# CH585SFR register map
Vendor: WCH Ltd.; Series: CH58x; File version: 1.0
WCH wireless MCU CH58x Family Support, Drivers
CPU: RISC-V r0p0, little endian, no MPU, no FPU, 2 interrupt priority bits
Registers are 8-bit, Read or Write, reset 0x0 unless marked. A register's access mark holds for its fields unless they carry their own. Offsets are from the block's base; lines under a group give offsets from that group; [hi:lo] are bit positions; {n}, {i} and the like mark numbered series; 'fields as' and 'values as' point back to an identical list; <NAME> marks a mode.

## Memory map
0x40001000 SYS size 0x400 — System Control Register
0x40001000 RTC blocks up to offset 0x3F — Real time clock
0x40001000 System_control blocks up to offset 0x54 — System control related registers
0x40001000 TouchKey blocks up to offset 0x58 — Touch buttons
0x40001000 ADC blocks up to offset 0x8E — Analog to Digital Converter
0x40001000 GPIO blocks up to offset 0xDC — General porpose intput output
0x40002000 TMR0 size 0x400 — Timer0 register
0x40002400 TMR1 size 0x400 — Timer1 register
0x40002800 TMR2 size 0x400 — Timer2 register
0x40002C00 TMR3 size 0x400 — Timer3 register
0x40003000 UART0 size 0x400
0x40003400 UART1 size 0x400
0x40003800 UART2 size 0x400
0x40003C00 UART3 size 0x400
0x40004000 SPI0 size 0x400
0x40004400 SPI1 size 0x400
0x40004800 I2C size 0x400
0x40005000 PWMx size 0x400
0x40006000 LCD size 0x400
0x40008000 USBFS size 0x400
0x40009000 USBHS size 0x400 — USB register
0x4000C000 BLE size 0x1400
0x4000F000 LED size 0x400
0xE000E000 PFIC size 0x1000 — Program Fast Interrupt Controller
0xE000F000 Systick size 0x100

## Interrupts
16 TMR0 (SYS, TMR0) — TMR0_IRQHandler
17 GPIOA (GPIO) — GPIOA_IRQHandler
17 GPIO_A (SYS) — GPIOA_IRQHandler
18 GPIOB (GPIO) — GPIOB_IRQHandler
18 GPIO_B (SYS) — GPIOB_IRQHandler
19 SPI0 (SYS, SPI0) — SPI0_IRQHandler
20 BLEB (SYS, BLE) — BB_IRQHandler
21 BLEL (SYS, BLE) — LLE_IRQHandler
22 USB (SYS) — USB_IRQHandler
22 USBFS — USB_IRQHandler
24 TMR1 (SYS, TMR1) — TMR1_IRQHandler
25 TMR2 (SYS, TMR2) — TMR2_IRQHandler
26 UART0 (SYS, UART0) — UART0_IRQHandler
27 UART1 (SYS, UART1) — UART1_IRQHandler
28 RTC (SYS, RTC) — RTC_IRQHandler
29 ADC (SYS, ADC) — ADC_IRQHandler
30 I2C (SYS, I2C) — I2C_IRQHandler
31 PWMX_SPI1 (SYS) — PWMX_SPI1_IRQHandler
31 PWMx — PPWMX_SPI1_IRQHandler
31 SPI1 — PWMX_SPI1_IRQHandler
32 TMR3 (SYS, TMR3) — TMR3_IRQHandler
33 UART2 (SYS, UART2) — UART2_IRQHandler
34 UART3 (SYS, UART3) — UART3_IRQHandler
35 WDOG_BAT (SYS, System_control) — WDOG_BAT_IRQHandler
36 NFC (SYS) — NFC_IRQHandler
37 USB2DEVICE (SYS) — USB2_DEVICE_IRQHandler
37 USBHS_DEVICE (USBHS) — USB2_DEVICE_IRQHandler
38 USB2HOST (SYS) — USB2_HOST_IRQHandler
38 USBHS_HOST (USBHS) — USB2_HOST_IRQHandler
39 LED (SYS, LED) — LED_IRQHandler

## RTC — Real time clock
Base 0x40001000
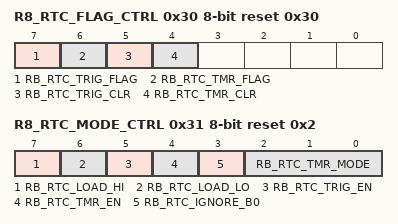
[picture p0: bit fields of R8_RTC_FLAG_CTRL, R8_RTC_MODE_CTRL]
0x30 R8_RTC_FLAG_CTRL reset 0x30 — RWA, Real time clock
  [7] RB_RTC_TRIG_FLAG ro — RO, RTC trigger action flag
  [6] RB_RTC_TMR_FLAG ro — RO, RTC timer action flag
  [5] RB_RTC_TRIG_CLR — RW, set 1 to clear RTC trigger action flag, auto clear
  [4] RB_RTC_TMR_CLR — RW, set 1 to clear RTC timer action flag, auto clear
0x31 R8_RTC_MODE_CTRL Read or Write under safe Accessing mode reset 0x2 — RWA, RTC mode control, SAM
  [7] RB_RTC_LOAD_HI — RWA, set 1 to load RTC count high word R32_RTC_CNT_DAY, auto clear after loaded
  [6] RB_RTC_LOAD_LO — RWA, set 1 to load RTC count low word R32_RTC_CNT_32K, auto clear after loaded
  [5] RB_RTC_TRIG_EN — RWA, RTC trigger mode enable
  [4] RB_RTC_TMR_EN — RWA, RTC timer mode enable
  [3] RB_RTC_IGNORE_B0 — RWA, force ignore bit0 for trigger mode: 0=compare bit0, 1=ignore bit0
  [2:0] RB_RTC_TMR_MODE — RWA, RTC timer mode: 000=0.125S, 001=0.25S, 010=0.5S, 011=1S, 100=2S, 101=4S, 110=8S, 111=16S
0x34 R32_RTC_TRIG 32-bit Read or Write under safe Accessing mode — RWA, RTC trigger value, SAM
  [31:0] R32_RTC_TRIG — RWA, RTC trigger value
0x38 R16_RTC_CNT_32K 16-bit ro reset not defined — RO, RTC count based 32KHz
  [15:0] R16_RTC_CNT_32K — R0,RTC count based 32KHz
0x3A R16_RTC_CNT_2S 16-bit ro reset not defined — RO, RTC count based 2 second
0x3C R32_RTC_CNT_DAY 32-bit ro reset not defined — RO, RTC count based one day, only low 14 bit
  [13:0] R32_RTC_CNT_DAY — RWA,RTC count based one day
